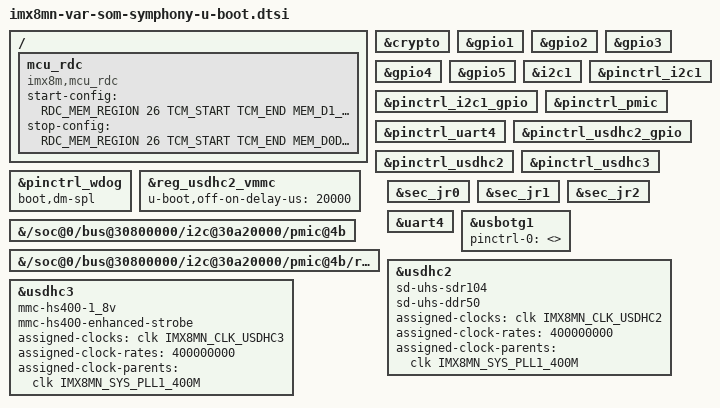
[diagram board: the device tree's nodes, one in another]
// SPDX-License-Identifier: GPL-2.0+
/*
 * Copyright 2019 NXP
 * Copyright 2025 Variscite Ltd.
 */

#include "imx8mn-u-boot.dtsi"
#include "imx8mn-sec-def.h"

/ {
	mcu_rdc {
		compatible = "imx8m,mcu_rdc";
		/* rdc config when MCU starts
		 * memory:
		 *   TCM --> Only Domian 1 can access (0x7E0000~0x81FFFF)
		 *   DDR --> Only Domian 1 can access (0x7E000000~0x7F000000)
		 * end.
		 */
		start-config = <
			    RDC_MEM_REGION 26 TCM_START TCM_END MEM_D1_ACCESS
			    RDC_MEM_REGION 0 M4_EVK_DDR4_START M4_EVK_DDR4_END MEM_D1_ACCESS
			    0x0 0x0 0x0 0x0 0x0
			  >;
		/* rdc config when MCU stops
		 * memory:
		 *   TCM --> domain 0/1 can access (0x7E0000~0x81FFFF)
		 *   DDR --> domain 0/1 can access (0x7E000000~0x7F000000)
		 * end.
		 */
		stop-config = <
			    RDC_MEM_REGION 26 TCM_START TCM_END MEM_D0D1_ACCESS
			    RDC_MEM_REGION 0 M4_EVK_DDR4_START M4_EVK_DDR4_END MEM_D0D1_ACCESS
			    0x0 0x0 0x0 0x0 0x0
			  >;
	};
};

&crypto {
	bootph-pre-ram;
};

&gpio1 {
	bootph-pre-ram;
};

&gpio2 {
	bootph-pre-ram;
};

&gpio3 {
	bootph-pre-ram;
};

&gpio4 {
	bootph-pre-ram;
};

&gpio5 {
	bootph-pre-ram;
};

&i2c1 {
	bootph-pre-ram;
};

&pinctrl_i2c1 {
	bootph-pre-ram;
};

&pinctrl_i2c1_gpio {
	bootph-pre-ram;
};

&pinctrl_pmic {
	bootph-pre-ram;
};

&pinctrl_uart4 {
	bootph-pre-ram;
};

&pinctrl_usdhc2_gpio {
	bootph-pre-ram;
};

&pinctrl_usdhc2 {
	bootph-pre-ram;
};

&pinctrl_usdhc3 {
	bootph-pre-ram;
};

&pinctrl_wdog {
	boot,dm-spl;
};

&reg_usdhc2_vmmc {
	bootph-pre-ram;
	u-boot,off-on-delay-us = <20000>;
};

&{/soc@0/bus@30800000/i2c@30a20000/pmic@4b} {
	bootph-pre-ram;
};

&{/soc@0/bus@30800000/i2c@30a20000/pmic@4b/regulators} {
	bootph-pre-ram;
};

&sec_jr0 {
	bootph-pre-ram;
};

&sec_jr1 {
	bootph-pre-ram;
};

&sec_jr2 {
	bootph-pre-ram;
};

&uart4 {
	bootph-pre-ram;
};

&usbotg1 {
	pinctrl-names = "default";
	pinctrl-0 = <>;
};

&usdhc2 {
	bootph-pre-ram;
	sd-uhs-sdr104;
	sd-uhs-ddr50;
	assigned-clocks = <&clk IMX8MN_CLK_USDHC2>;
	assigned-clock-rates = <400000000>;
	assigned-clock-parents = <&clk IMX8MN_SYS_PLL1_400M>;
};

&usdhc3 {
	bootph-pre-ram;
	mmc-hs400-1_8v;
	mmc-hs400-enhanced-strobe;
	assigned-clocks = <&clk IMX8MN_CLK_USDHC3>;
	assigned-clock-rates = <400000000>;
	assigned-clock-parents = <&clk IMX8MN_SYS_PLL1_400M>;
};
